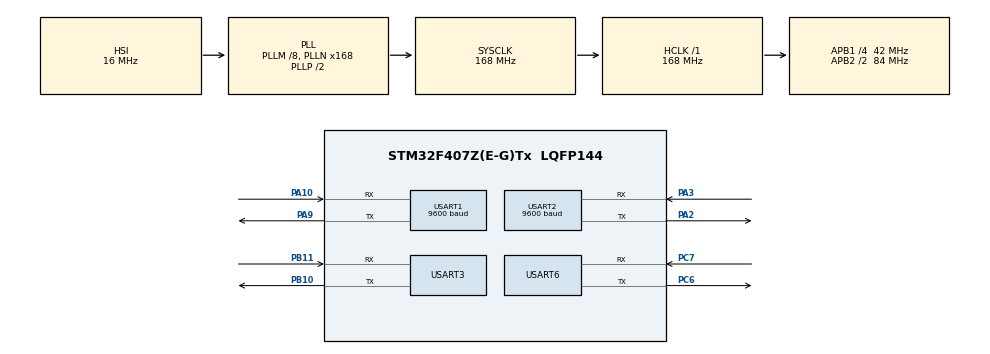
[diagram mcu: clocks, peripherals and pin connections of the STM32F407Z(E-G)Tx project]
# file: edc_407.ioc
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Dma.Request0=USART2_RX
Dma.Request1=USART2_TX
Dma.Request2=USART3_RX
Dma.Request3=USART3_TX
Dma.Request4=USART1_RX
Dma.Request5=USART1_TX
Dma.USART1_RX.4.Direction=DMA_PERIPH_TO_MEMORY
Dma.USART1_RX.4.FIFOMode=DMA_FIFOMODE_DISABLE
Dma.USART1_RX.4.Instance=DMA2_Stream2
Dma.USART1_RX.4.MemDataAlignment=DMA_MDATAALIGN_BYTE
Dma.USART1_RX.4.MemInc=DMA_MINC_ENABLE
Dma.USART1_RX.4.Mode=DMA_NORMAL
Dma.USART1_RX.4.PeriphDataAlignment=DMA_PDATAALIGN_BYTE
Dma.USART1_RX.4.PeriphInc=DMA_PINC_DISABLE
Dma.USART1_RX.4.Priority=DMA_PRIORITY_LOW
Dma.USART1_TX.5.Direction=DMA_MEMORY_TO_PERIPH
Dma.USART1_TX.5.FIFOMode=DMA_FIFOMODE_DISABLE
Dma.USART1_TX.5.Instance=DMA2_Stream7
Dma.USART1_TX.5.MemDataAlignment=DMA_MDATAALIGN_BYTE
Dma.USART1_TX.5.MemInc=DMA_MINC_ENABLE
Dma.USART1_TX.5.Mode=DMA_NORMAL
Dma.USART1_TX.5.PeriphDataAlignment=DMA_PDATAALIGN_BYTE
Dma.USART1_TX.5.PeriphInc=DMA_PINC_DISABLE
Dma.USART1_TX.5.Priority=DMA_PRIORITY_LOW
Dma.USART2_RX.0.Direction=DMA_PERIPH_TO_MEMORY
Dma.USART2_RX.0.FIFOMode=DMA_FIFOMODE_DISABLE
Dma.USART2_RX.0.Instance=DMA1_Stream5
Dma.USART2_RX.0.MemDataAlignment=DMA_MDATAALIGN_BYTE
Dma.USART2_RX.0.MemInc=DMA_MINC_ENABLE
Dma.USART2_RX.0.Mode=DMA_NORMAL
Dma.USART2_RX.0.PeriphDataAlignment=DMA_PDATAALIGN_BYTE
Dma.USART2_RX.0.PeriphInc=DMA_PINC_DISABLE
Dma.USART2_RX.0.Priority=DMA_PRIORITY_LOW
Dma.USART2_TX.1.Direction=DMA_MEMORY_TO_PERIPH
Dma.USART2_TX.1.FIFOMode=DMA_FIFOMODE_DISABLE
Dma.USART2_TX.1.Instance=DMA1_Stream6
Dma.USART2_TX.1.MemDataAlignment=DMA_MDATAALIGN_BYTE
Dma.USART2_TX.1.MemInc=DMA_MINC_ENABLE
Dma.USART2_TX.1.Mode=DMA_NORMAL
Dma.USART2_TX.1.PeriphDataAlignment=DMA_PDATAALIGN_BYTE
Dma.USART2_TX.1.PeriphInc=DMA_PINC_DISABLE
Dma.USART2_TX.1.Priority=DMA_PRIORITY_LOW
Dma.USART3_RX.2.Direction=DMA_PERIPH_TO_MEMORY
Dma.USART3_RX.2.FIFOMode=DMA_FIFOMODE_DISABLE
Dma.USART3_RX.2.Instance=DMA1_Stream1
Dma.USART3_RX.2.MemDataAlignment=DMA_MDATAALIGN_BYTE
Dma.USART3_RX.2.MemInc=DMA_MINC_ENABLE
Dma.USART3_RX.2.Mode=DMA_NORMAL
Dma.USART3_RX.2.PeriphDataAlignment=DMA_PDATAALIGN_BYTE
Dma.USART3_RX.2.PeriphInc=DMA_PINC_DISABLE
Dma.USART3_RX.2.Priority=DMA_PRIORITY_LOW
Dma.USART3_TX.3.Direction=DMA_MEMORY_TO_PERIPH
Dma.USART3_TX.3.FIFOMode=DMA_FIFOMODE_DISABLE
Dma.USART3_TX.3.Instance=DMA1_Stream3
Dma.USART3_TX.3.MemDataAlignment=DMA_MDATAALIGN_BYTE
Dma.USART3_TX.3.MemInc=DMA_MINC_ENABLE
Dma.USART3_TX.3.Mode=DMA_NORMAL
Dma.USART3_TX.3.PeriphDataAlignment=DMA_PDATAALIGN_BYTE
Dma.USART3_TX.3.PeriphInc=DMA_PINC_DISABLE
Dma.USART3_TX.3.Priority=DMA_PRIORITY_LOW
Mcu.Family=STM32F4
Mcu.Name=STM32F407Z(E-G)Tx
Mcu.Package=LQFP144
NVIC.DMA1_Stream1_IRQn=true\:0\:0\:false\:false\:true\:false\:true
NVIC.DMA1_Stream3_IRQn=true\:0\:0\:false\:false\:true\:false\:true
NVIC.DMA1_Stream5_IRQn=true\:0\:0\:false\:false\:true\:false\:true
NVIC.DMA1_Stream6_IRQn=true\:0\:0\:false\:false\:true\:false\:true
NVIC.DMA2_Stream2_IRQn=true\:0\:0\:false\:false\:true\:false\:true
NVIC.DMA2_Stream7_IRQn=true\:0\:0\:false\:false\:true\:false\:true
NVIC.PriorityGroup=NVIC_PRIORITYGROUP_4
NVIC.USART1_IRQn=true\:0\:0\:false\:false\:true\:true\:true
NVIC.USART2_IRQn=true\:0\:0\:false\:false\:true\:true\:true
NVIC.USART3_IRQn=true\:0\:0\:false\:false\:true\:true\:true
NVIC.USART6_IRQn=true\:0\:0\:false\:false\:true\:true\:true
PA10.Mode=Asynchronous
PA10.Signal=USART1_RX
PA2.Mode=Asynchronous
PA2.Signal=USART2_TX
PA3.Mode=Asynchronous
PA3.Signal=USART2_RX
PA9.Mode=Asynchronous
PA9.Signal=USART1_TX
PB10.Mode=Asynchronous
PB10.Signal=USART3_TX
PB11.Mode=Asynchronous
PB11.Signal=USART3_RX
PC6.Mode=Asynchronous
PC6.Signal=USART6_TX
PC7.Mode=Asynchronous
PC7.Signal=USART6_RX
PH0-OSC_IN.Mode=HSE-External-Oscillator
PH0-OSC_IN.Signal=RCC_OSC_IN
PH1-OSC_OUT.Mode=HSE-External-Oscillator
PH1-OSC_OUT.Signal=RCC_OSC_OUT
ProjectManager.HeapSize=0x200
ProjectManager.StackSize=0x400
ProjectManager.TargetToolchain=MDK-ARM V5
RCC.48MHZClocksFreq_Value=84000000
RCC.AHBFreq_Value=168000000
RCC.APB1CLKDivider=RCC_HCLK_DIV4
RCC.APB1Freq_Value=42000000
RCC.APB1TimFreq_Value=84000000
RCC.APB2CLKDivider=RCC_HCLK_DIV2
RCC.APB2Freq_Value=84000000
RCC.APB2TimFreq_Value=168000000
RCC.CortexFreq_Value=168000000
RCC.HCLKFreq_Value=168000000
RCC.HSE_VALUE=25000000
RCC.HSI_VALUE=16000000
RCC.LSE_VALUE=32768
RCC.PLLM=8
RCC.PLLN=168
RCC.SYSCLKFreq_VALUE=168000000
RCC.SYSCLKSource=RCC_SYSCLKSOURCE_PLLCLK
RCC.VCOOutputFreq_Value=336000000
USART1.BaudRate=9600
USART1.VirtualMode=VM_ASYNC
USART2.BaudRate=9600
USART2.VirtualMode=VM_ASYNC
USART3.VirtualMode=VM_ASYNC
USART6.VirtualMode=VM_ASYNC
board=custom

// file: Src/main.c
/* USER CODE BEGIN Header */
/**
  ******************************************************************************
  * @file           : main.c
  * @brief          : Main program body
  ******************************************************************************
  * @attention
  *
  * <h2><center>&copy; Copyright (c) 2020 STMicroelectronics.
  * All rights reserved.</center></h2>
  *
  * This software component is licensed by ST under BSD 3-Clause license,
  * the "License"; You may not use this file except in compliance with the
  * License. You may obtain a copy of the License at:
  *                        opensource.org/licenses/BSD-3-Clause
  *
  ******************************************************************************
  */
/* USER CODE END Header */

#include "main.h"
#include "dma.h"
#include "usart.h"
#include "gpio.h"
#include "zigbee.h"
#include "bluetooth.h"
#include "mpu.h"
#include "config.h"

/* USER CODE BEGIN PV */
speed3axistype speed_xyr={0x80,0x00,0x79,0x2A,0x80,0x00};
mpuData an_data;
uint8_t mpuRxbuf_[1]={0};
/* USER CODE END PV */

void SystemClock_Config(void);
extern void mpu_task(mpuData * data);
extern void usart_task(speed3axistype *speed);

/* USER CODE BEGIN 0 */
static void uDelay(uint32_t t)
{
	uint32_t i;
	for(i=0;i<t;++i)
		__nop();
}

/* USER CODE END 0 */

int main(void)
{

  /* MCU Configuration--------------------------------------------------------*/

  /* Reset of all peripherals, Initializes the Flash interface and the Systick. */
  HAL_Init();

  /* Configure the system clock */
  SystemClock_Config();

  /* Initialize all configured peripherals */
  MX_GPIO_Init();
  MX_DMA_Init();
  MX_USART1_UART_Init();
  MX_USART2_UART_Init();
  MX_USART3_UART_Init();
  MX_USART6_UART_Init();

  /* USER CODE BEGIN 2 */
  zigbee_Init(&huart6);
  /* USER CODE END 2 */
  printf("test message\n");
  /* Infinite loop */
  /* USER CODE BEGIN WHILE */
  while (1)
  {
		mpu_task(&an_data);
		printf("an_vel: %f, an: %f \r\n", an_data.an_vel, an_data.an);
    /* USER CODE END WHILE */
		usart_task(&speed_xyr);
		uDelay(100);
  }
}

void SystemClock_Config(void)
{
  RCC_OscInitTypeDef RCC_OscInitStruct = {0};
  RCC_ClkInitTypeDef RCC_ClkInitStruct = {0};

  /** Configure the main internal regulator output voltage
  */
  __HAL_RCC_PWR_CLK_ENABLE();
  __HAL_PWR_VOLTAGESCALING_CONFIG(PWR_REGULATOR_VOLTAGE_SCALE1);
  /** Initializes the CPU, AHB and APB busses clocks
  */
  RCC_OscInitStruct.OscillatorType = RCC_OSCILLATORTYPE_HSI;
  RCC_OscInitStruct.HSIState = RCC_HSI_ON;
  RCC_OscInitStruct.HSICalibrationValue = RCC_HSICALIBRATION_DEFAULT;
  RCC_OscInitStruct.PLL.PLLState = RCC_PLL_ON;
  RCC_OscInitStruct.PLL.PLLSource = RCC_PLLSOURCE_HSI;
  RCC_OscInitStruct.PLL.PLLM = 8;
  RCC_OscInitStruct.PLL.PLLN = 168;
  RCC_OscInitStruct.PLL.PLLP = RCC_PLLP_DIV2;
  RCC_OscInitStruct.PLL.PLLQ = 4;
  if (HAL_RCC_OscConfig(&RCC_OscInitStruct) != HAL_OK)
  {
    Error_Handler();
  }
  /** Initializes the CPU, AHB and APB busses clocks
  */
  RCC_ClkInitStruct.ClockType = RCC_CLOCKTYPE_HCLK|RCC_CLOCKTYPE_SYSCLK
                              |RCC_CLOCKTYPE_PCLK1|RCC_CLOCKTYPE_PCLK2;
  RCC_ClkInitStruct.SYSCLKSource = RCC_SYSCLKSOURCE_PLLCLK;
  RCC_ClkInitStruct.AHBCLKDivider = RCC_SYSCLK_DIV1;
  RCC_ClkInitStruct.APB1CLKDivider = RCC_HCLK_DIV4;
  RCC_ClkInitStruct.APB2CLKDivider = RCC_HCLK_DIV2;

  if (HAL_RCC_ClockConfig(&RCC_ClkInitStruct, FLASH_LATENCY_5) != HAL_OK)
  {
    Error_Handler();
  }
}

void Error_Handler(void)
{
}

/************************ (C) COPYRIGHT STMicroelectronics *****END OF FILE****/
